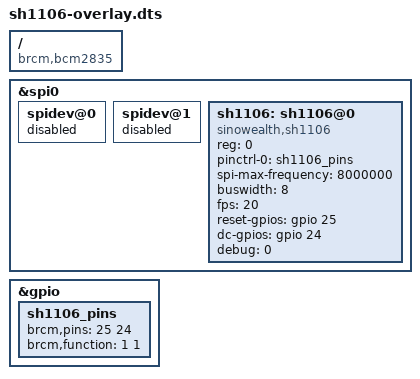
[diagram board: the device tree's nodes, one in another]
/*
 * sh1106-overlay.dts
 *
 * -------------------------------------------------
 * 
 * -------------------------------------------------
 * Device---Driver-----BUS       GPIO's
 * display  sh1106  spi0.0    25 24
 * Based on  tinylcd35-overlay.dts
 * 7/12/2017  -- Anthony Campbell  Initial Device tree framework
 */

/dts-v1/;
/plugin/;

/ {
	compatible = "brcm,bcm2835", "brcm,bcm2708", "brcm,bcm2709";

	fragment@0 {
		target = <&spi0>;
		__overlay__ {
			status = "okay";

			spidev@0{
				status = "disabled";
			};

			spidev@1{
				status = "disabled";
			};
		};
	};

	fragment@1 {
		target = <&gpio>;
		__overlay__ {
			sh1106_pins: sh1106_pins {
				brcm,pins = <25 24>;
				brcm,function = <1 1>; /* out */
			};
		};
	};

	fragment@2 {
		target = <&spi0>;
		__overlay__ {
			/* needed to avoid dtc warning */
			#address-cells = <1>;
			#size-cells = <0>;

			sh1106: sh1106@0{
				compatible = "sinowealth,sh1106";
				reg = <0>;
				pinctrl-names = "default";
				pinctrl-0 = <&sh1106_pins>;
				spi-max-frequency = <8000000>;
				buswidth = <8>;
				fps = <20>;
				reset-gpios = <&gpio 25 0>;
				dc-gpios = <&gpio 24 0>;
				debug = <0>;

			};

		};
	};

	__overrides__ {
		speed =      <&sh1106>,"spi-max-frequency:0";
		rotate =     <&sh1106>,"rotate:0";
		fps =        <&sh1106>,"fps:0";
		debug =      <&sh1106>,"debug:0";
	};
};
